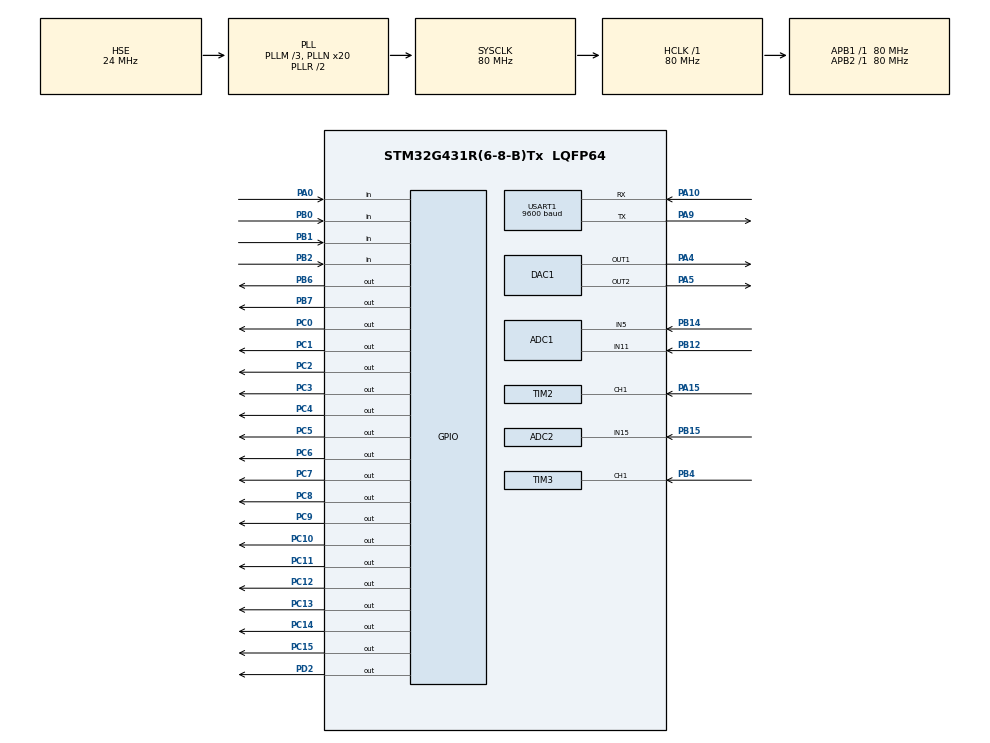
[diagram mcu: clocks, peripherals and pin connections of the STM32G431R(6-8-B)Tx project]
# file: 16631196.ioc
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ADC1.Channel-0\#ChannelRegularConversion=ADC_CHANNEL_11
ADC1.Channel-1\#ChannelRegularConversion=ADC_CHANNEL_5
ADC1.ClockPrescaler=ADC_CLOCK_SYNC_PCLK_DIV4
ADC1.ContinuousConvMode=ENABLE
ADC1.DMAContinuousRequests=ENABLE
ADC1.NbrOfConversion=2
ADC1.NbrOfConversionFlag=1
ADC1.OffsetNumber-0\#ChannelRegularConversion=ADC_OFFSET_NONE
ADC1.OffsetNumber-1\#ChannelRegularConversion=ADC_OFFSET_NONE
ADC1.Rank-0\#ChannelRegularConversion=1
ADC1.Rank-1\#ChannelRegularConversion=2
ADC1.SamplingTime-0\#ChannelRegularConversion=ADC_SAMPLETIME_24CYCLES_5
ADC1.SamplingTime-1\#ChannelRegularConversion=ADC_SAMPLETIME_24CYCLES_5
ADC1.master=1
ADC2.Channel-0\#ChannelRegularConversion=ADC_CHANNEL_15
ADC2.ClockPrescaler=ADC_CLOCK_SYNC_PCLK_DIV4
ADC2.ContinuousConvMode=ENABLE
ADC2.DMAContinuousRequests=ENABLE
ADC2.NbrOfConversionFlag=1
ADC2.OffsetNumber-0\#ChannelRegularConversion=ADC_OFFSET_NONE
ADC2.Rank-0\#ChannelRegularConversion=1
ADC2.SamplingTime-0\#ChannelRegularConversion=ADC_SAMPLETIME_24CYCLES_5
DAC1.DAC_Channel-DAC_OUT2=DAC_CHANNEL_2
Dma.ADC1.4.Direction=DMA_PERIPH_TO_MEMORY
Dma.ADC1.4.EventEnable=DISABLE
Dma.ADC1.4.Instance=DMA1_Channel5
Dma.ADC1.4.MemDataAlignment=DMA_MDATAALIGN_WORD
Dma.ADC1.4.MemInc=DMA_MINC_ENABLE
Dma.ADC1.4.Mode=DMA_CIRCULAR
Dma.ADC1.4.PeriphDataAlignment=DMA_PDATAALIGN_WORD
Dma.ADC1.4.PeriphInc=DMA_PINC_DISABLE
Dma.ADC1.4.Polarity=HAL_DMAMUX_REQ_GEN_RISING
Dma.ADC1.4.Priority=DMA_PRIORITY_MEDIUM
Dma.ADC1.4.RequestNumber=1
Dma.ADC1.4.SignalID=NONE
Dma.ADC1.4.SyncEnable=DISABLE
Dma.ADC1.4.SyncPolarity=HAL_DMAMUX_SYNC_NO_EVENT
Dma.ADC1.4.SyncRequestNumber=1
Dma.ADC1.4.SyncSignalID=NONE
Dma.ADC2.5.Direction=DMA_PERIPH_TO_MEMORY
Dma.ADC2.5.EventEnable=DISABLE
Dma.ADC2.5.Instance=DMA1_Channel6
Dma.ADC2.5.MemDataAlignment=DMA_MDATAALIGN_WORD
Dma.ADC2.5.MemInc=DMA_MINC_ENABLE
Dma.ADC2.5.Mode=DMA_CIRCULAR
Dma.ADC2.5.PeriphDataAlignment=DMA_PDATAALIGN_WORD
Dma.ADC2.5.PeriphInc=DMA_PINC_DISABLE
Dma.ADC2.5.Polarity=HAL_DMAMUX_REQ_GEN_RISING
Dma.ADC2.5.Priority=DMA_PRIORITY_MEDIUM
Dma.ADC2.5.RequestNumber=1
Dma.ADC2.5.SignalID=NONE
Dma.ADC2.5.SyncEnable=DISABLE
Dma.ADC2.5.SyncPolarity=HAL_DMAMUX_SYNC_NO_EVENT
Dma.ADC2.5.SyncRequestNumber=1
Dma.ADC2.5.SyncSignalID=NONE
Dma.Request0=TIM2_CH1
Dma.Request1=TIM2_CH2
Dma.Request2=TIM3_CH1
Dma.Request3=TIM3_CH2
Dma.Request4=ADC1
Dma.Request5=ADC2
Dma.Request6=USART1_RX
Dma.TIM2_CH1.0.Direction=DMA_PERIPH_TO_MEMORY
Dma.TIM2_CH1.0.EventEnable=DISABLE
Dma.TIM2_CH1.0.Instance=DMA1_Channel1
Dma.TIM2_CH1.0.MemDataAlignment=DMA_MDATAALIGN_WORD
Dma.TIM2_CH1.0.MemInc=DMA_MINC_ENABLE
Dma.TIM2_CH1.0.Mode=DMA_CIRCULAR
Dma.TIM2_CH1.0.PeriphDataAlignment=DMA_PDATAALIGN_WORD
Dma.TIM2_CH1.0.PeriphInc=DMA_PINC_DISABLE
Dma.TIM2_CH1.0.Polarity=HAL_DMAMUX_REQ_GEN_RISING
Dma.TIM2_CH1.0.Priority=DMA_PRIORITY_LOW
Dma.TIM2_CH1.0.RequestNumber=1
Dma.TIM2_CH1.0.SignalID=NONE
Dma.TIM2_CH1.0.SyncEnable=DISABLE
Dma.TIM2_CH1.0.SyncPolarity=HAL_DMAMUX_SYNC_NO_EVENT
Dma.TIM2_CH1.0.SyncRequestNumber=1
Dma.TIM2_CH1.0.SyncSignalID=NONE
Dma.TIM2_CH2.1.Direction=DMA_PERIPH_TO_MEMORY
Dma.TIM2_CH2.1.EventEnable=DISABLE
Dma.TIM2_CH2.1.Instance=DMA1_Channel2
Dma.TIM2_CH2.1.MemDataAlignment=DMA_MDATAALIGN_WORD
Dma.TIM2_CH2.1.MemInc=DMA_MINC_ENABLE
Dma.TIM2_CH2.1.Mode=DMA_CIRCULAR
Dma.TIM2_CH2.1.PeriphDataAlignment=DMA_PDATAALIGN_WORD
Dma.TIM2_CH2.1.PeriphInc=DMA_PINC_DISABLE
Dma.TIM2_CH2.1.Polarity=HAL_DMAMUX_REQ_GEN_RISING
Dma.TIM2_CH2.1.Priority=DMA_PRIORITY_LOW
Dma.TIM2_CH2.1.RequestNumber=1
Dma.TIM2_CH2.1.SignalID=NONE
Dma.TIM2_CH2.1.SyncEnable=DISABLE
Dma.TIM2_CH2.1.SyncPolarity=HAL_DMAMUX_SYNC_NO_EVENT
Dma.TIM2_CH2.1.SyncRequestNumber=1
Dma.TIM2_CH2.1.SyncSignalID=NONE
Dma.TIM3_CH1.2.Direction=DMA_PERIPH_TO_MEMORY
Dma.TIM3_CH1.2.EventEnable=DISABLE
Dma.TIM3_CH1.2.Instance=DMA1_Channel3
Dma.TIM3_CH1.2.MemDataAlignment=DMA_MDATAALIGN_WORD
Dma.TIM3_CH1.2.MemInc=DMA_MINC_ENABLE
Dma.TIM3_CH1.2.Mode=DMA_CIRCULAR
Dma.TIM3_CH1.2.PeriphDataAlignment=DMA_PDATAALIGN_WORD
Dma.TIM3_CH1.2.PeriphInc=DMA_PINC_DISABLE
Dma.TIM3_CH1.2.Polarity=HAL_DMAMUX_REQ_GEN_RISING
Dma.TIM3_CH1.2.Priority=DMA_PRIORITY_LOW
Dma.TIM3_CH1.2.RequestNumber=1
Dma.TIM3_CH1.2.SignalID=NONE
Dma.TIM3_CH1.2.SyncEnable=DISABLE
Dma.TIM3_CH1.2.SyncPolarity=HAL_DMAMUX_SYNC_NO_EVENT
Dma.TIM3_CH1.2.SyncRequestNumber=1
Dma.TIM3_CH1.2.SyncSignalID=NONE
Dma.TIM3_CH2.3.Direction=DMA_PERIPH_TO_MEMORY
Dma.TIM3_CH2.3.EventEnable=DISABLE
Dma.TIM3_CH2.3.Instance=DMA1_Channel4
Dma.TIM3_CH2.3.MemDataAlignment=DMA_MDATAALIGN_WORD
Dma.TIM3_CH2.3.MemInc=DMA_MINC_ENABLE
Dma.TIM3_CH2.3.Mode=DMA_CIRCULAR
Dma.TIM3_CH2.3.PeriphDataAlignment=DMA_PDATAALIGN_WORD
Dma.TIM3_CH2.3.PeriphInc=DMA_PINC_DISABLE
Dma.TIM3_CH2.3.Polarity=HAL_DMAMUX_REQ_GEN_RISING
Dma.TIM3_CH2.3.Priority=DMA_PRIORITY_LOW
Dma.TIM3_CH2.3.RequestNumber=1
Dma.TIM3_CH2.3.SignalID=NONE
Dma.TIM3_CH2.3.SyncEnable=DISABLE
Dma.TIM3_CH2.3.SyncPolarity=HAL_DMAMUX_SYNC_NO_EVENT
Dma.TIM3_CH2.3.SyncRequestNumber=1
Dma.TIM3_CH2.3.SyncSignalID=NONE
Dma.USART1_RX.6.Direction=DMA_PERIPH_TO_MEMORY
Dma.USART1_RX.6.EventEnable=DISABLE
Dma.USART1_RX.6.Instance=DMA2_Channel1
Dma.USART1_RX.6.MemDataAlignment=DMA_MDATAALIGN_BYTE
Dma.USART1_RX.6.MemInc=DMA_MINC_ENABLE
Dma.USART1_RX.6.Mode=DMA_NORMAL
Dma.USART1_RX.6.PeriphDataAlignment=DMA_PDATAALIGN_BYTE
Dma.USART1_RX.6.PeriphInc=DMA_PINC_DISABLE
Dma.USART1_RX.6.Polarity=HAL_DMAMUX_REQ_GEN_RISING
Dma.USART1_RX.6.Priority=DMA_PRIORITY_HIGH
Dma.USART1_RX.6.RequestNumber=1
Dma.USART1_RX.6.SignalID=NONE
Dma.USART1_RX.6.SyncEnable=DISABLE
Dma.USART1_RX.6.SyncPolarity=HAL_DMAMUX_SYNC_NO_EVENT
Dma.USART1_RX.6.SyncRequestNumber=1
Dma.USART1_RX.6.SyncSignalID=NONE
Mcu.Family=STM32G4
Mcu.Name=STM32G431R(6-8-B)Tx
Mcu.Package=LQFP64
NVIC.DMA1_Channel1_IRQn=true\:0\:0\:false\:false\:true\:false\:true
NVIC.DMA1_Channel2_IRQn=true\:0\:0\:false\:false\:true\:false\:true
NVIC.DMA1_Channel3_IRQn=true\:0\:0\:false\:false\:true\:false\:true
NVIC.DMA1_Channel4_IRQn=true\:0\:0\:false\:false\:true\:false\:true
NVIC.DMA1_Channel5_IRQn=true\:0\:0\:false\:false\:true\:false\:true
NVIC.DMA1_Channel6_IRQn=true\:0\:0\:false\:false\:true\:false\:true
NVIC.DMA2_Channel1_IRQn=true\:0\:0\:false\:false\:true\:false\:true
NVIC.PriorityGroup=NVIC_PRIORITYGROUP_4
NVIC.RTC_Alarm_IRQn=true\:0\:0\:false\:false\:true\:true\:true
NVIC.USART1_IRQn=true\:0\:0\:false\:false\:true\:true\:true
PA0.Signal=GPIO_Input
PA10.Mode=Asynchronous
PA10.Signal=USART1_RX
PA13.Mode=Serial_Wire
PA13.Signal=SYS_JTMS-SWDIO
PA14.Mode=Serial_Wire
PA14.Signal=SYS_JTCK-SWCLK
PA15.Signal=S_TIM2_CH1
PA4.Signal=COMP_DAC11_group
PA5.Signal=COMP_DAC12_group
PA9.Mode=Asynchronous
PA9.Signal=USART1_TX
PB0.Signal=GPIO_Input
PB1.Signal=GPIO_Input
PB12.Mode=IN11-Single-Ended
PB12.Signal=ADC1_IN11
PB14.Mode=IN5-Single-Ended
PB14.Signal=ADC1_IN5
PB15.Mode=IN15-Single-Ended
PB15.Signal=ADC2_IN15
PB2.Signal=GPIO_Input
PB4.Signal=S_TIM3_CH1
PB6.Signal=GPIO_Output
PB7.Signal=GPIO_Output
PC0.Signal=GPIO_Output
PC1.Signal=GPIO_Output
PC10.Signal=GPIO_Output
PC11.Signal=GPIO_Output
PC12.Signal=GPIO_Output
PC13.Signal=GPIO_Output
PC14-OSC32_IN.Signal=GPIO_Output
PC15-OSC32_OUT.Signal=GPIO_Output
PC2.Signal=GPIO_Output
PC3.Signal=GPIO_Output
PC4.Signal=GPIO_Output
PC5.Signal=GPIO_Output
PC6.Signal=GPIO_Output
PC7.Signal=GPIO_Output
PC8.Signal=GPIO_Output
PC9.Signal=GPIO_Output
PD2.Signal=GPIO_Output
PF0-OSC_IN.Mode=HSE-External-Oscillator
PF0-OSC_IN.Signal=RCC_OSC_IN
PF1-OSC_OUT.Mode=HSE-External-Oscillator
PF1-OSC_OUT.Signal=RCC_OSC_OUT
ProjectManager.HeapSize=0x200
ProjectManager.StackSize=0x400
ProjectManager.TargetToolchain=MDK-ARM V5.27
RCC.ADC12Freq_Value=80000000
RCC.AHBFreq_Value=80000000
RCC.APB1Freq_Value=80000000
RCC.APB1TimFreq_Value=80000000
RCC.APB2Freq_Value=80000000
RCC.APB2TimFreq_Value=80000000
RCC.CortexFreq_Value=80000000
RCC.EXTERNAL_CLOCK_VALUE=12288000
RCC.HCLKFreq_Value=80000000
RCC.HSE_VALUE=24000000
RCC.HSI48_VALUE=48000000
RCC.HSI_VALUE=16000000
RCC.LSE_VALUE=32768
RCC.PLLM=RCC_PLLM_DIV3
RCC.PLLN=20
RCC.PLLSourceVirtual=RCC_PLLSOURCE_HSE
RCC.RTCClockSelection=RCC_RTCCLKSOURCE_HSE_DIV32
RCC.SYSCLKFreq_VALUE=80000000
RCC.SYSCLKSource=RCC_SYSCLKSOURCE_PLLCLK
RCC.USBFreq_Value=80000000
RCC.VCOOutputFreq_Value=160000000
RTC.Alarm-Alarm\ A=RTC_ALARM_A
RTC.AlarmMaskDateWeekDay-Alarm\ A=RTC_ALARMMASK_DATEWEEKDAY
RTC.AsynchPrediv=125-1
RTC.Format=RTC_FORMAT_BIN
RTC.Seconds_A-Alarm\ A=30
RTC.SynchPrediv=6000-1
SH.COMP_DAC11_group.0=DAC1_OUT1,DAC_OUT1
SH.COMP_DAC12_group.0=DAC1_OUT2,DAC_OUT2
SH.S_TIM2_CH1.0=TIM2_CH1,TriggerSource_TI1FP1
SH.S_TIM2_CH1.1=TIM2_CH1,Input_Capture1_from_TI1
SH.S_TIM2_CH1.2=TIM2_CH1,Input_Capture2_from_TI1
SH.S_TIM3_CH1.0=TIM3_CH1,TriggerSource_TI1FP1
SH.S_TIM3_CH1.1=TIM3_CH1,Input_Capture1_from_TI1
SH.S_TIM3_CH1.2=TIM3_CH1,Input_Capture2_from_TI1
TIM2.Channel-Input_Capture1_from_TI1=TIM_CHANNEL_1
TIM2.Channel-Input_Capture2_from_TI1=TIM_CHANNEL_2
TIM2.ICPolarity_CH2=TIM_INPUTCHANNELPOLARITY_FALLING
TIM2.Prescaler=16-1
TIM3.Channel-Input_Capture1_from_TI1=TIM_CHANNEL_1
TIM3.Channel-Input_Capture2_from_TI1=TIM_CHANNEL_2
TIM3.ICPolarity_CH2=TIM_INPUTCHANNELPOLARITY_FALLING
TIM3.Prescaler=16-1
USART1.BaudRate=9600
USART1.VirtualMode-Asynchronous=VM_ASYNC
VP_RTC_VS_RTC_Activate.Mode=RTC_Enabled
VP_RTC_VS_RTC_Alarm_A_Intern.Mode=Alarm A
VP_RTC_VS_RTC_Calendar.Mode=RTC_Calendar
VP_SYS_VS_DBSignals.Mode=DisableDeadBatterySignals
VP_TIM2_VS_ClockSourceINT.Mode=Internal
VP_TIM2_VS_ControllerModeReset.Mode=Reset Mode
VP_TIM3_VS_ClockSourceINT.Mode=Internal
VP_TIM3_VS_ControllerModeReset.Mode=Reset Mode
board=custom

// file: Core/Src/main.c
/* USER CODE BEGIN Header */
/**
  ******************************************************************************
  * @file           : main.c
  * @brief          : Main program body
  ******************************************************************************
  * @attention
  *
  * <h2><center>&copy; Copyright (c) 2025 STMicroelectronics.
  * All rights reserved.</center></h2>
  *
  * This software component is licensed by ST under BSD 3-Clause license,
  * the "License"; You may not use this file except in compliance with the
  * License. You may obtain a copy of the License at:
  *                        opensource.org/licenses/BSD-3-Clause
  *
  ******************************************************************************
  */
/* USER CODE END Header */
#include "main.h"
#include "adc.h"
#include "dac.h"
#include "dma.h"
#include "rtc.h"
#include "tim.h"
#include "usart.h"
#include "gpio.h"

/* USER CODE BEGIN Includes */
#include "system.h"
/* USER CODE END Includes */

void SystemClock_Config(void);

int main(void)
{

  /* MCU Configuration--------------------------------------------------------*/

  /* Reset of all peripherals, Initializes the Flash interface and the Systick. */
  HAL_Init();

  /* Configure the system clock */
  SystemClock_Config();

  /* Initialize all configured peripherals */
  MX_GPIO_Init();
  MX_DMA_Init();
  MX_TIM2_Init();
  MX_TIM3_Init();
  MX_ADC1_Init();
  MX_ADC2_Init();
  MX_USART1_UART_Init();
  MX_RTC_Init();
  MX_DAC1_Init();
  /* USER CODE BEGIN 2 */
	I2CInit();

	adc_init();
	dac_init();

	lcd_init();
	led_renew();
	tims_init();
  /* USER CODE END 2 */

  /* Infinite loop */
  while (1)
  {

    /* USER CODE BEGIN 3 */
		uart_proc();
		scheduler_run();
  }
  /* USER CODE END 3 */
}

void SystemClock_Config(void)
{
  RCC_OscInitTypeDef RCC_OscInitStruct = {0};
  RCC_ClkInitTypeDef RCC_ClkInitStruct = {0};
  RCC_PeriphCLKInitTypeDef PeriphClkInit = {0};

  /** Configure the main internal regulator output voltage
  */
  HAL_PWREx_ControlVoltageScaling(PWR_REGULATOR_VOLTAGE_SCALE1);
  /** Initializes the RCC Oscillators according to the specified parameters
  * in the RCC_OscInitTypeDef structure.
  */
  RCC_OscInitStruct.OscillatorType = RCC_OSCILLATORTYPE_HSE;
  RCC_OscInitStruct.HSEState = RCC_HSE_ON;
  RCC_OscInitStruct.PLL.PLLState = RCC_PLL_ON;
  RCC_OscInitStruct.PLL.PLLSource = RCC_PLLSOURCE_HSE;
  RCC_OscInitStruct.PLL.PLLM = RCC_PLLM_DIV3;
  RCC_OscInitStruct.PLL.PLLN = 20;
  RCC_OscInitStruct.PLL.PLLP = RCC_PLLP_DIV2;
  RCC_OscInitStruct.PLL.PLLQ = RCC_PLLQ_DIV2;
  RCC_OscInitStruct.PLL.PLLR = RCC_PLLR_DIV2;
  if (HAL_RCC_OscConfig(&RCC_OscInitStruct) != HAL_OK)
  {
    Error_Handler();
  }
  /** Initializes the CPU, AHB and APB buses clocks
  */
  RCC_ClkInitStruct.ClockType = RCC_CLOCKTYPE_HCLK|RCC_CLOCKTYPE_SYSCLK
                              |RCC_CLOCKTYPE_PCLK1|RCC_CLOCKTYPE_PCLK2;
  RCC_ClkInitStruct.SYSCLKSource = RCC_SYSCLKSOURCE_PLLCLK;
  RCC_ClkInitStruct.AHBCLKDivider = RCC_SYSCLK_DIV1;
  RCC_ClkInitStruct.APB1CLKDivider = RCC_HCLK_DIV1;
  RCC_ClkInitStruct.APB2CLKDivider = RCC_HCLK_DIV1;

  if (HAL_RCC_ClockConfig(&RCC_ClkInitStruct, FLASH_LATENCY_2) != HAL_OK)
  {
    Error_Handler();
  }
  /** Initializes the peripherals clocks
  */
  PeriphClkInit.PeriphClockSelection = RCC_PERIPHCLK_RTC|RCC_PERIPHCLK_USART1
                              |RCC_PERIPHCLK_ADC12;
  PeriphClkInit.Usart1ClockSelection = RCC_USART1CLKSOURCE_PCLK2;
  PeriphClkInit.Adc12ClockSelection = RCC_ADC12CLKSOURCE_SYSCLK;
  PeriphClkInit.RTCClockSelection = RCC_RTCCLKSOURCE_HSE_DIV32;

  if (HAL_RCCEx_PeriphCLKConfig(&PeriphClkInit) != HAL_OK)
  {
    Error_Handler();
  }
}

void Error_Handler(void)
{
  __disable_irq();
  while (1)
  {
  }
}

/************************ (C) COPYRIGHT STMicroelectronics *****END OF FILE****/
